VERSION ""

NS_ :

BS_:

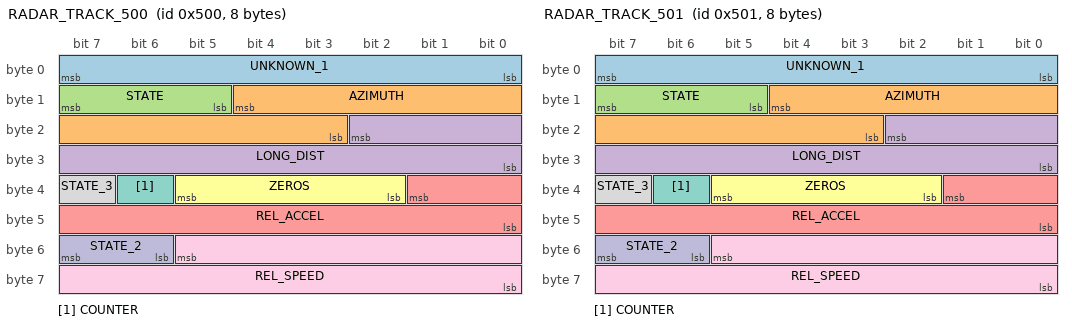
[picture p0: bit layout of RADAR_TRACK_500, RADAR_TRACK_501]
BO_ 1280 RADAR_TRACK_500: 8 RADAR
 SG_ UNKNOWN_1 : 7|8@0- (1,0) [-128|127] "" XXX
 SG_ AZIMUTH : 12|10@0- (0.2,0) [-102.4|102.2] "" XXX
 SG_ STATE : 15|3@0+ (1,0) [0|7] "" XXX
 SG_ LONG_DIST : 18|11@0+ (0.1,0) [0|204.7] "" XXX
 SG_ REL_ACCEL : 33|10@0- (0.02,0) [-10.24|10.22] "" XXX
 SG_ ZEROS : 37|4@0+ (1,0) [0|255] "" XXX
 SG_ COUNTER : 38|1@0+ (1,0) [0|1] "" XXX
 SG_ STATE_3 : 39|1@0+ (1,0) [0|1] "" XXX
 SG_ REL_SPEED : 53|14@0- (0.01,0) [-81.92|81.92] "" XXX
 SG_ STATE_2 : 55|2@0+ (1,0) [0|3] "" XXX

BO_ 1281 RADAR_TRACK_501: 8 RADAR
 SG_ UNKNOWN_1 : 7|8@0- (1,0) [-128|127] "" XXX
 SG_ AZIMUTH : 12|10@0- (0.2,0) [-102.4|102.2] "" XXX
 SG_ STATE : 15|3@0+ (1,0) [0|7] "" XXX
 SG_ LONG_DIST : 18|11@0+ (0.1,0) [0|204.7] "" XXX
 SG_ REL_ACCEL : 33|10@0- (0.02,0) [-10.24|10.22] "" XXX
 SG_ ZEROS : 37|4@0+ (1,0) [0|255] "" XXX
 SG_ COUNTER : 38|1@0+ (1,0) [0|1] "" XXX
 SG_ STATE_3 : 39|1@0+ (1,0) [0|1] "" XXX
 SG_ REL_SPEED : 53|14@0- (0.01,0) [-81.92|81.92] "" XXX
 SG_ STATE_2 : 55|2@0+ (1,0) [0|3] "" XXX

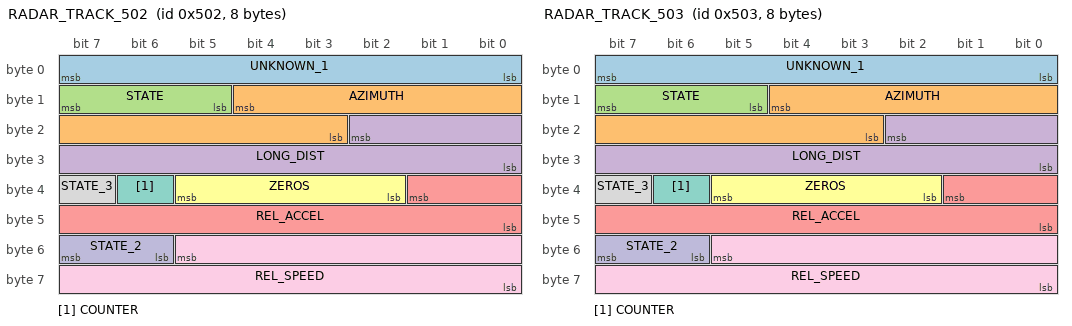
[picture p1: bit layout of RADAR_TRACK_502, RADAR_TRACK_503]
BO_ 1282 RADAR_TRACK_502: 8 RADAR
 SG_ UNKNOWN_1 : 7|8@0- (1,0) [-128|127] "" XXX
 SG_ AZIMUTH : 12|10@0- (0.2,0) [-102.4|102.2] "" XXX
 SG_ STATE : 15|3@0+ (1,0) [0|7] "" XXX
 SG_ LONG_DIST : 18|11@0+ (0.1,0) [0|204.7] "" XXX
 SG_ REL_ACCEL : 33|10@0- (0.02,0) [-10.24|10.22] "" XXX
 SG_ ZEROS : 37|4@0+ (1,0) [0|255] "" XXX
 SG_ COUNTER : 38|1@0+ (1,0) [0|1] "" XXX
 SG_ STATE_3 : 39|1@0+ (1,0) [0|1] "" XXX
 SG_ REL_SPEED : 53|14@0- (0.01,0) [-81.92|81.92] "" XXX
 SG_ STATE_2 : 55|2@0+ (1,0) [0|3] "" XXX

BO_ 1283 RADAR_TRACK_503: 8 RADAR
 SG_ UNKNOWN_1 : 7|8@0- (1,0) [-128|127] "" XXX
 SG_ AZIMUTH : 12|10@0- (0.2,0) [-102.4|102.2] "" XXX
 SG_ STATE : 15|3@0+ (1,0) [0|7] "" XXX
 SG_ LONG_DIST : 18|11@0+ (0.1,0) [0|204.7] "" XXX
 SG_ REL_ACCEL : 33|10@0- (0.02,0) [-10.24|10.22] "" XXX
 SG_ ZEROS : 37|4@0+ (1,0) [0|255] "" XXX
 SG_ COUNTER : 38|1@0+ (1,0) [0|1] "" XXX
 SG_ STATE_3 : 39|1@0+ (1,0) [0|1] "" XXX
 SG_ REL_SPEED : 53|14@0- (0.01,0) [-81.92|81.92] "" XXX
 SG_ STATE_2 : 55|2@0+ (1,0) [0|3] "" XXX

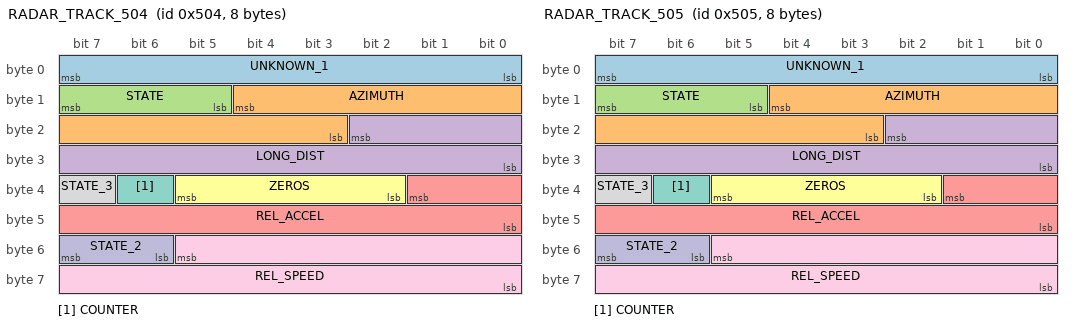
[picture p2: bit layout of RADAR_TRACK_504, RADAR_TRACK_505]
BO_ 1284 RADAR_TRACK_504: 8 RADAR
 SG_ UNKNOWN_1 : 7|8@0- (1,0) [-128|127] "" XXX
 SG_ AZIMUTH : 12|10@0- (0.2,0) [-102.4|102.2] "" XXX
 SG_ STATE : 15|3@0+ (1,0) [0|7] "" XXX
 SG_ LONG_DIST : 18|11@0+ (0.1,0) [0|204.7] "" XXX
 SG_ REL_ACCEL : 33|10@0- (0.02,0) [-10.24|10.22] "" XXX
 SG_ ZEROS : 37|4@0+ (1,0) [0|255] "" XXX
 SG_ COUNTER : 38|1@0+ (1,0) [0|1] "" XXX
 SG_ STATE_3 : 39|1@0+ (1,0) [0|1] "" XXX
 SG_ REL_SPEED : 53|14@0- (0.01,0) [-81.92|81.92] "" XXX
 SG_ STATE_2 : 55|2@0+ (1,0) [0|3] "" XXX

BO_ 1285 RADAR_TRACK_505: 8 RADAR
 SG_ UNKNOWN_1 : 7|8@0- (1,0) [-128|127] "" XXX
 SG_ AZIMUTH : 12|10@0- (0.2,0) [-102.4|102.2] "" XXX
 SG_ STATE : 15|3@0+ (1,0) [0|7] "" XXX
 SG_ LONG_DIST : 18|11@0+ (0.1,0) [0|204.7] "" XXX
 SG_ REL_ACCEL : 33|10@0- (0.02,0) [-10.24|10.22] "" XXX
 SG_ ZEROS : 37|4@0+ (1,0) [0|255] "" XXX
 SG_ COUNTER : 38|1@0+ (1,0) [0|1] "" XXX
 SG_ STATE_3 : 39|1@0+ (1,0) [0|1] "" XXX
 SG_ REL_SPEED : 53|14@0- (0.01,0) [-81.92|81.92] "" XXX
 SG_ STATE_2 : 55|2@0+ (1,0) [0|3] "" XXX

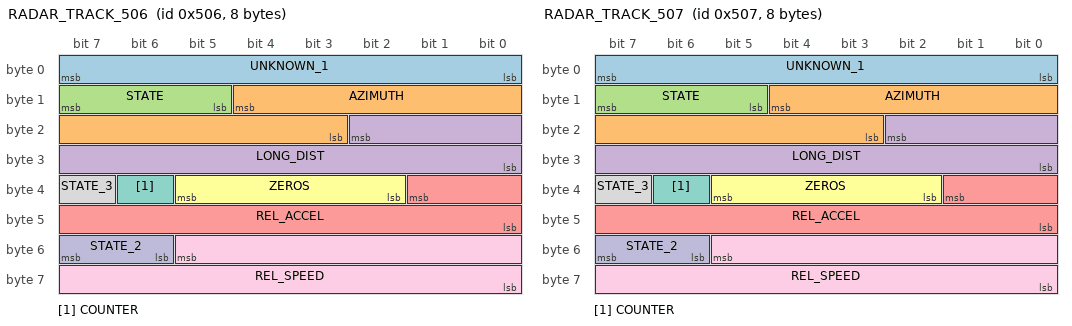
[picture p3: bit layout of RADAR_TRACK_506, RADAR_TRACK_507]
BO_ 1286 RADAR_TRACK_506: 8 RADAR
 SG_ UNKNOWN_1 : 7|8@0- (1,0) [-128|127] "" XXX
 SG_ AZIMUTH : 12|10@0- (0.2,0) [-102.4|102.2] "" XXX
 SG_ STATE : 15|3@0+ (1,0) [0|7] "" XXX
 SG_ LONG_DIST : 18|11@0+ (0.1,0) [0|204.7] "" XXX
 SG_ REL_ACCEL : 33|10@0- (0.02,0) [-10.24|10.22] "" XXX
 SG_ ZEROS : 37|4@0+ (1,0) [0|255] "" XXX
 SG_ COUNTER : 38|1@0+ (1,0) [0|1] "" XXX
 SG_ STATE_3 : 39|1@0+ (1,0) [0|1] "" XXX
 SG_ REL_SPEED : 53|14@0- (0.01,0) [-81.92|81.92] "" XXX
 SG_ STATE_2 : 55|2@0+ (1,0) [0|3] "" XXX

BO_ 1287 RADAR_TRACK_507: 8 RADAR
 SG_ UNKNOWN_1 : 7|8@0- (1,0) [-128|127] "" XXX
 SG_ AZIMUTH : 12|10@0- (0.2,0) [-102.4|102.2] "" XXX
 SG_ STATE : 15|3@0+ (1,0) [0|7] "" XXX
 SG_ LONG_DIST : 18|11@0+ (0.1,0) [0|204.7] "" XXX
 SG_ REL_ACCEL : 33|10@0- (0.02,0) [-10.24|10.22] "" XXX
 SG_ ZEROS : 37|4@0+ (1,0) [0|255] "" XXX
 SG_ COUNTER : 38|1@0+ (1,0) [0|1] "" XXX
 SG_ STATE_3 : 39|1@0+ (1,0) [0|1] "" XXX
 SG_ REL_SPEED : 53|14@0- (0.01,0) [-81.92|81.92] "" XXX
 SG_ STATE_2 : 55|2@0+ (1,0) [0|3] "" XXX

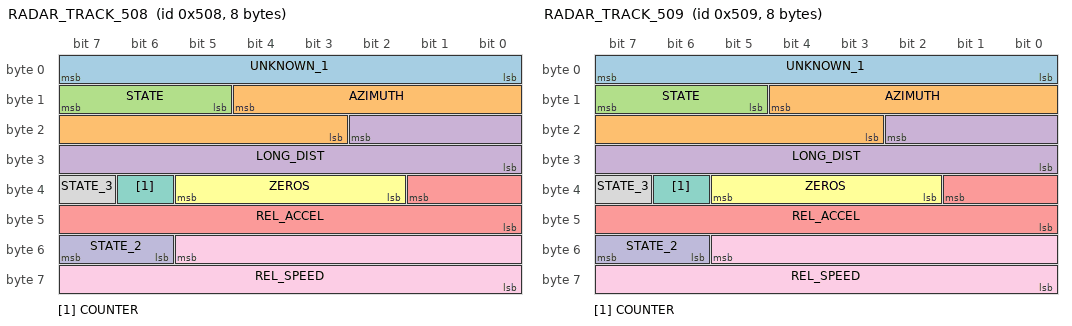
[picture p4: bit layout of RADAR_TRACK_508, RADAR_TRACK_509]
BO_ 1288 RADAR_TRACK_508: 8 RADAR
 SG_ UNKNOWN_1 : 7|8@0- (1,0) [-128|127] "" XXX
 SG_ AZIMUTH : 12|10@0- (0.2,0) [-102.4|102.2] "" XXX
 SG_ STATE : 15|3@0+ (1,0) [0|7] "" XXX
 SG_ LONG_DIST : 18|11@0+ (0.1,0) [0|204.7] "" XXX
 SG_ REL_ACCEL : 33|10@0- (0.02,0) [-10.24|10.22] "" XXX
 SG_ ZEROS : 37|4@0+ (1,0) [0|255] "" XXX
 SG_ COUNTER : 38|1@0+ (1,0) [0|1] "" XXX
 SG_ STATE_3 : 39|1@0+ (1,0) [0|1] "" XXX
 SG_ REL_SPEED : 53|14@0- (0.01,0) [-81.92|81.92] "" XXX
 SG_ STATE_2 : 55|2@0+ (1,0) [0|3] "" XXX

BO_ 1289 RADAR_TRACK_509: 8 RADAR
 SG_ UNKNOWN_1 : 7|8@0- (1,0) [-128|127] "" XXX
 SG_ AZIMUTH : 12|10@0- (0.2,0) [-102.4|102.2] "" XXX
 SG_ STATE : 15|3@0+ (1,0) [0|7] "" XXX
 SG_ LONG_DIST : 18|11@0+ (0.1,0) [0|204.7] "" XXX
 SG_ REL_ACCEL : 33|10@0- (0.02,0) [-10.24|10.22] "" XXX
 SG_ ZEROS : 37|4@0+ (1,0) [0|255] "" XXX
 SG_ COUNTER : 38|1@0+ (1,0) [0|1] "" XXX
 SG_ STATE_3 : 39|1@0+ (1,0) [0|1] "" XXX
 SG_ REL_SPEED : 53|14@0- (0.01,0) [-81.92|81.92] "" XXX
 SG_ STATE_2 : 55|2@0+ (1,0) [0|3] "" XXX

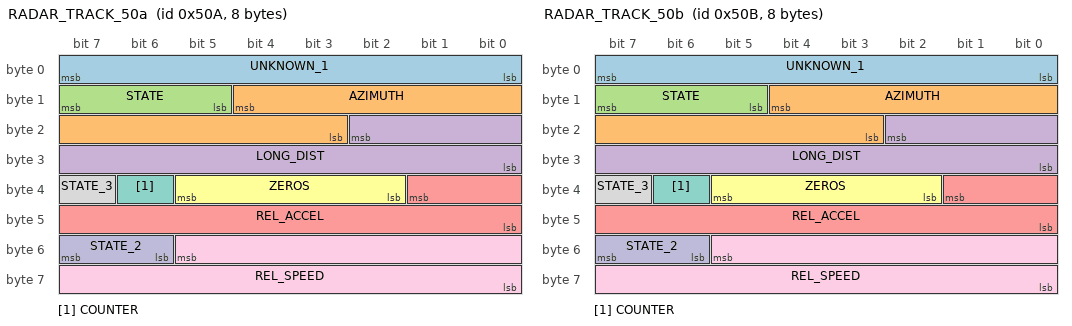
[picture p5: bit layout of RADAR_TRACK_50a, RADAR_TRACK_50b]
BO_ 1290 RADAR_TRACK_50a: 8 RADAR
 SG_ UNKNOWN_1 : 7|8@0- (1,0) [-128|127] "" XXX
 SG_ AZIMUTH : 12|10@0- (0.2,0) [-102.4|102.2] "" XXX
 SG_ STATE : 15|3@0+ (1,0) [0|7] "" XXX
 SG_ LONG_DIST : 18|11@0+ (0.1,0) [0|204.7] "" XXX
 SG_ REL_ACCEL : 33|10@0- (0.02,0) [-10.24|10.22] "" XXX
 SG_ ZEROS : 37|4@0+ (1,0) [0|255] "" XXX
 SG_ COUNTER : 38|1@0+ (1,0) [0|1] "" XXX
 SG_ STATE_3 : 39|1@0+ (1,0) [0|1] "" XXX
 SG_ REL_SPEED : 53|14@0- (0.01,0) [-81.92|81.92] "" XXX
 SG_ STATE_2 : 55|2@0+ (1,0) [0|3] "" XXX

BO_ 1291 RADAR_TRACK_50b: 8 RADAR
 SG_ UNKNOWN_1 : 7|8@0- (1,0) [-128|127] "" XXX
 SG_ AZIMUTH : 12|10@0- (0.2,0) [-102.4|102.2] "" XXX
 SG_ STATE : 15|3@0+ (1,0) [0|7] "" XXX
 SG_ LONG_DIST : 18|11@0+ (0.1,0) [0|204.7] "" XXX
 SG_ REL_ACCEL : 33|10@0- (0.02,0) [-10.24|10.22] "" XXX
 SG_ ZEROS : 37|4@0+ (1,0) [0|255] "" XXX
 SG_ COUNTER : 38|1@0+ (1,0) [0|1] "" XXX
 SG_ STATE_3 : 39|1@0+ (1,0) [0|1] "" XXX
 SG_ REL_SPEED : 53|14@0- (0.01,0) [-81.92|81.92] "" XXX
 SG_ STATE_2 : 55|2@0+ (1,0) [0|3] "" XXX

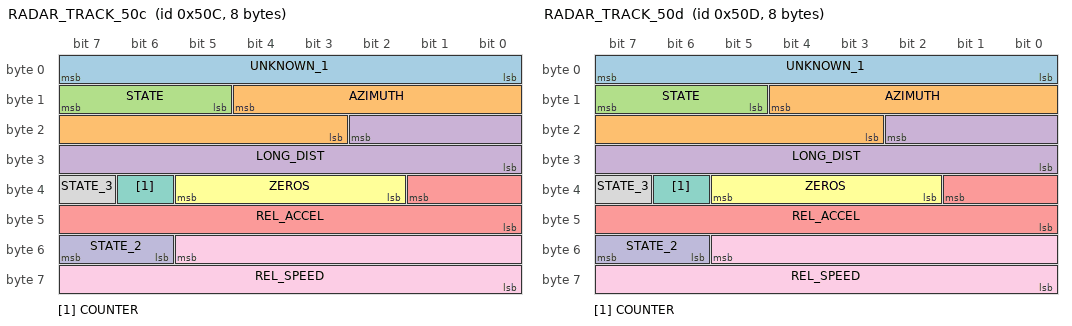
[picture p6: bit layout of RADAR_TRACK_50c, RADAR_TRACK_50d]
BO_ 1292 RADAR_TRACK_50c: 8 RADAR
 SG_ UNKNOWN_1 : 7|8@0- (1,0) [-128|127] "" XXX
 SG_ AZIMUTH : 12|10@0- (0.2,0) [-102.4|102.2] "" XXX
 SG_ STATE : 15|3@0+ (1,0) [0|7] "" XXX
 SG_ LONG_DIST : 18|11@0+ (0.1,0) [0|204.7] "" XXX
 SG_ REL_ACCEL : 33|10@0- (0.02,0) [-10.24|10.22] "" XXX
 SG_ ZEROS : 37|4@0+ (1,0) [0|255] "" XXX
 SG_ COUNTER : 38|1@0+ (1,0) [0|1] "" XXX
 SG_ STATE_3 : 39|1@0+ (1,0) [0|1] "" XXX
 SG_ REL_SPEED : 53|14@0- (0.01,0) [-81.92|81.92] "" XXX
 SG_ STATE_2 : 55|2@0+ (1,0) [0|3] "" XXX

BO_ 1293 RADAR_TRACK_50d: 8 RADAR
 SG_ UNKNOWN_1 : 7|8@0- (1,0) [-128|127] "" XXX
 SG_ AZIMUTH : 12|10@0- (0.2,0) [-102.4|102.2] "" XXX
 SG_ STATE : 15|3@0+ (1,0) [0|7] "" XXX
 SG_ LONG_DIST : 18|11@0+ (0.1,0) [0|204.7] "" XXX
 SG_ REL_ACCEL : 33|10@0- (0.02,0) [-10.24|10.22] "" XXX
 SG_ ZEROS : 37|4@0+ (1,0) [0|255] "" XXX
 SG_ COUNTER : 38|1@0+ (1,0) [0|1] "" XXX
 SG_ STATE_3 : 39|1@0+ (1,0) [0|1] "" XXX
 SG_ REL_SPEED : 53|14@0- (0.01,0) [-81.92|81.92] "" XXX
 SG_ STATE_2 : 55|2@0+ (1,0) [0|3] "" XXX

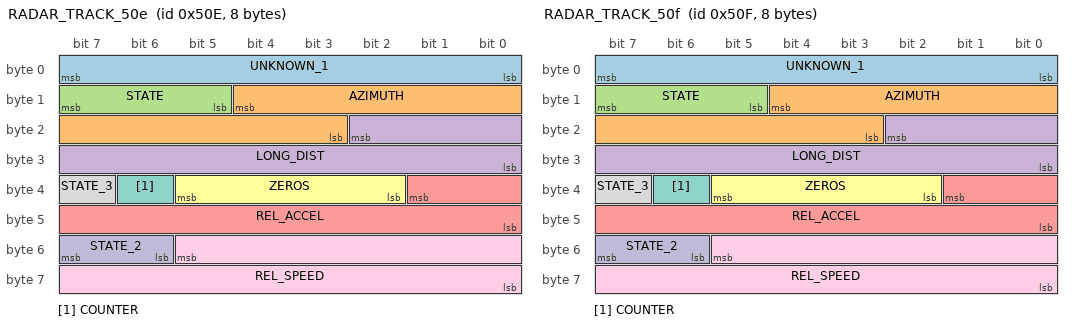
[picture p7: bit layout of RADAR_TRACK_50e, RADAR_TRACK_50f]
BO_ 1294 RADAR_TRACK_50e: 8 RADAR
 SG_ UNKNOWN_1 : 7|8@0- (1,0) [-128|127] "" XXX
 SG_ AZIMUTH : 12|10@0- (0.2,0) [-102.4|102.2] "" XXX
 SG_ STATE : 15|3@0+ (1,0) [0|7] "" XXX
 SG_ LONG_DIST : 18|11@0+ (0.1,0) [0|204.7] "" XXX
 SG_ REL_ACCEL : 33|10@0- (0.02,0) [-10.24|10.22] "" XXX
 SG_ ZEROS : 37|4@0+ (1,0) [0|255] "" XXX
 SG_ COUNTER : 38|1@0+ (1,0) [0|1] "" XXX
 SG_ STATE_3 : 39|1@0+ (1,0) [0|1] "" XXX
 SG_ REL_SPEED : 53|14@0- (0.01,0) [-81.92|81.92] "" XXX
 SG_ STATE_2 : 55|2@0+ (1,0) [0|3] "" XXX

BO_ 1295 RADAR_TRACK_50f: 8 RADAR
 SG_ UNKNOWN_1 : 7|8@0- (1,0) [-128|127] "" XXX
 SG_ AZIMUTH : 12|10@0- (0.2,0) [-102.4|102.2] "" XXX
 SG_ STATE : 15|3@0+ (1,0) [0|7] "" XXX
 SG_ LONG_DIST : 18|11@0+ (0.1,0) [0|204.7] "" XXX
 SG_ REL_ACCEL : 33|10@0- (0.02,0) [-10.24|10.22] "" XXX
 SG_ ZEROS : 37|4@0+ (1,0) [0|255] "" XXX
 SG_ COUNTER : 38|1@0+ (1,0) [0|1] "" XXX
 SG_ STATE_3 : 39|1@0+ (1,0) [0|1] "" XXX
 SG_ REL_SPEED : 53|14@0- (0.01,0) [-81.92|81.92] "" XXX
 SG_ STATE_2 : 55|2@0+ (1,0) [0|3] "" XXX

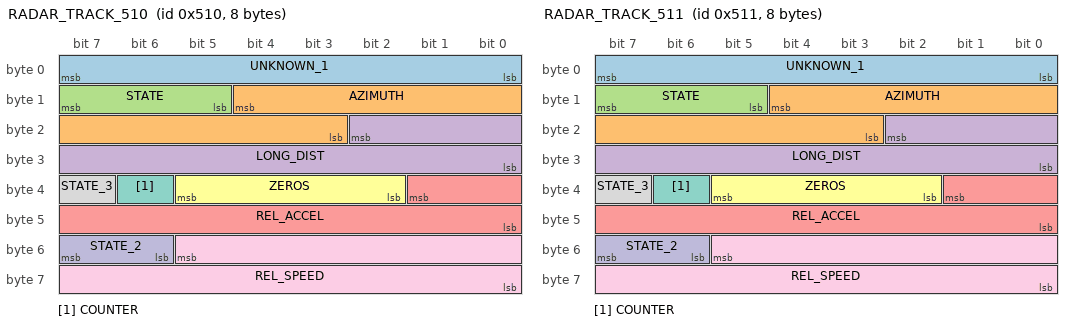
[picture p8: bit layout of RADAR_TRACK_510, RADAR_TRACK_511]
BO_ 1296 RADAR_TRACK_510: 8 RADAR
 SG_ UNKNOWN_1 : 7|8@0- (1,0) [-128|127] "" XXX
 SG_ AZIMUTH : 12|10@0- (0.2,0) [-102.4|102.2] "" XXX
 SG_ STATE : 15|3@0+ (1,0) [0|7] "" XXX
 SG_ LONG_DIST : 18|11@0+ (0.1,0) [0|204.7] "" XXX
 SG_ REL_ACCEL : 33|10@0- (0.02,0) [-10.24|10.22] "" XXX
 SG_ ZEROS : 37|4@0+ (1,0) [0|255] "" XXX
 SG_ COUNTER : 38|1@0+ (1,0) [0|1] "" XXX
 SG_ STATE_3 : 39|1@0+ (1,0) [0|1] "" XXX
 SG_ REL_SPEED : 53|14@0- (0.01,0) [-81.92|81.92] "" XXX
 SG_ STATE_2 : 55|2@0+ (1,0) [0|3] "" XXX

BO_ 1297 RADAR_TRACK_511: 8 RADAR
 SG_ UNKNOWN_1 : 7|8@0- (1,0) [-128|127] "" XXX
 SG_ AZIMUTH : 12|10@0- (0.2,0) [-102.4|102.2] "" XXX
 SG_ STATE : 15|3@0+ (1,0) [0|7] "" XXX
 SG_ LONG_DIST : 18|11@0+ (0.1,0) [0|204.7] "" XXX
 SG_ REL_ACCEL : 33|10@0- (0.02,0) [-10.24|10.22] "" XXX
 SG_ ZEROS : 37|4@0+ (1,0) [0|255] "" XXX
 SG_ COUNTER : 38|1@0+ (1,0) [0|1] "" XXX
 SG_ STATE_3 : 39|1@0+ (1,0) [0|1] "" XXX
 SG_ REL_SPEED : 53|14@0- (0.01,0) [-81.92|81.92] "" XXX
 SG_ STATE_2 : 55|2@0+ (1,0) [0|3] "" XXX

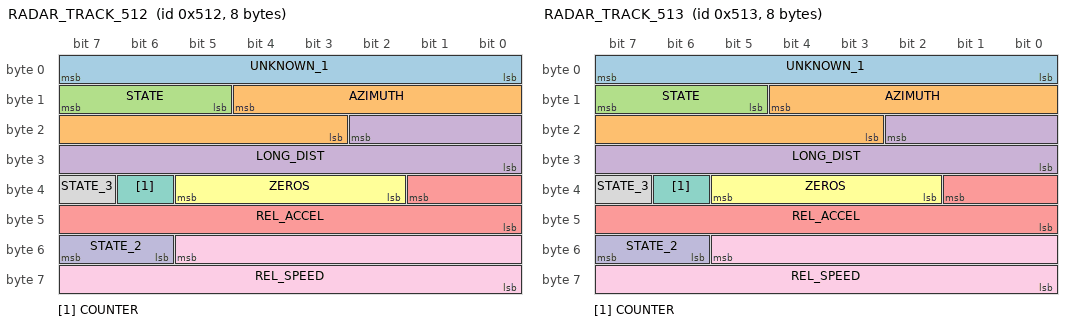
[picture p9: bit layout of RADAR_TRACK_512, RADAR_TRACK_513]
BO_ 1298 RADAR_TRACK_512: 8 RADAR
 SG_ UNKNOWN_1 : 7|8@0- (1,0) [-128|127] "" XXX
 SG_ AZIMUTH : 12|10@0- (0.2,0) [-102.4|102.2] "" XXX
 SG_ STATE : 15|3@0+ (1,0) [0|7] "" XXX
 SG_ LONG_DIST : 18|11@0+ (0.1,0) [0|204.7] "" XXX
 SG_ REL_ACCEL : 33|10@0- (0.02,0) [-10.24|10.22] "" XXX
 SG_ ZEROS : 37|4@0+ (1,0) [0|255] "" XXX
 SG_ COUNTER : 38|1@0+ (1,0) [0|1] "" XXX
 SG_ STATE_3 : 39|1@0+ (1,0) [0|1] "" XXX
 SG_ REL_SPEED : 53|14@0- (0.01,0) [-81.92|81.92] "" XXX
 SG_ STATE_2 : 55|2@0+ (1,0) [0|3] "" XXX

BO_ 1299 RADAR_TRACK_513: 8 RADAR
 SG_ UNKNOWN_1 : 7|8@0- (1,0) [-128|127] "" XXX
 SG_ AZIMUTH : 12|10@0- (0.2,0) [-102.4|102.2] "" XXX
 SG_ STATE : 15|3@0+ (1,0) [0|7] "" XXX
 SG_ LONG_DIST : 18|11@0+ (0.1,0) [0|204.7] "" XXX
 SG_ REL_ACCEL : 33|10@0- (0.02,0) [-10.24|10.22] "" XXX
 SG_ ZEROS : 37|4@0+ (1,0) [0|255] "" XXX
 SG_ COUNTER : 38|1@0+ (1,0) [0|1] "" XXX
 SG_ STATE_3 : 39|1@0+ (1,0) [0|1] "" XXX
 SG_ REL_SPEED : 53|14@0- (0.01,0) [-81.92|81.92] "" XXX
 SG_ STATE_2 : 55|2@0+ (1,0) [0|3] "" XXX

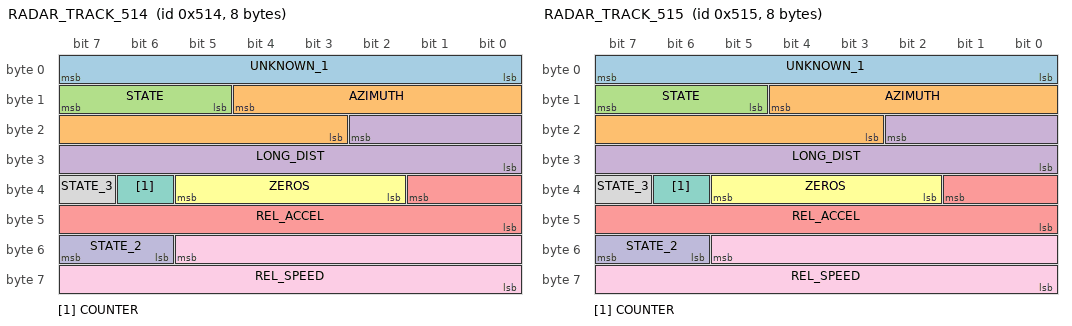
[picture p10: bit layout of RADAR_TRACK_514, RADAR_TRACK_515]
BO_ 1300 RADAR_TRACK_514: 8 RADAR
 SG_ UNKNOWN_1 : 7|8@0- (1,0) [-128|127] "" XXX
 SG_ AZIMUTH : 12|10@0- (0.2,0) [-102.4|102.2] "" XXX
 SG_ STATE : 15|3@0+ (1,0) [0|7] "" XXX
 SG_ LONG_DIST : 18|11@0+ (0.1,0) [0|204.7] "" XXX
 SG_ REL_ACCEL : 33|10@0- (0.02,0) [-10.24|10.22] "" XXX
 SG_ ZEROS : 37|4@0+ (1,0) [0|255] "" XXX
 SG_ COUNTER : 38|1@0+ (1,0) [0|1] "" XXX
 SG_ STATE_3 : 39|1@0+ (1,0) [0|1] "" XXX
 SG_ REL_SPEED : 53|14@0- (0.01,0) [-81.92|81.92] "" XXX
 SG_ STATE_2 : 55|2@0+ (1,0) [0|3] "" XXX

BO_ 1301 RADAR_TRACK_515: 8 RADAR
 SG_ UNKNOWN_1 : 7|8@0- (1,0) [-128|127] "" XXX
 SG_ AZIMUTH : 12|10@0- (0.2,0) [-102.4|102.2] "" XXX
 SG_ STATE : 15|3@0+ (1,0) [0|7] "" XXX
 SG_ LONG_DIST : 18|11@0+ (0.1,0) [0|204.7] "" XXX
 SG_ REL_ACCEL : 33|10@0- (0.02,0) [-10.24|10.22] "" XXX
 SG_ ZEROS : 37|4@0+ (1,0) [0|255] "" XXX
 SG_ COUNTER : 38|1@0+ (1,0) [0|1] "" XXX
 SG_ STATE_3 : 39|1@0+ (1,0) [0|1] "" XXX
 SG_ REL_SPEED : 53|14@0- (0.01,0) [-81.92|81.92] "" XXX
 SG_ STATE_2 : 55|2@0+ (1,0) [0|3] "" XXX

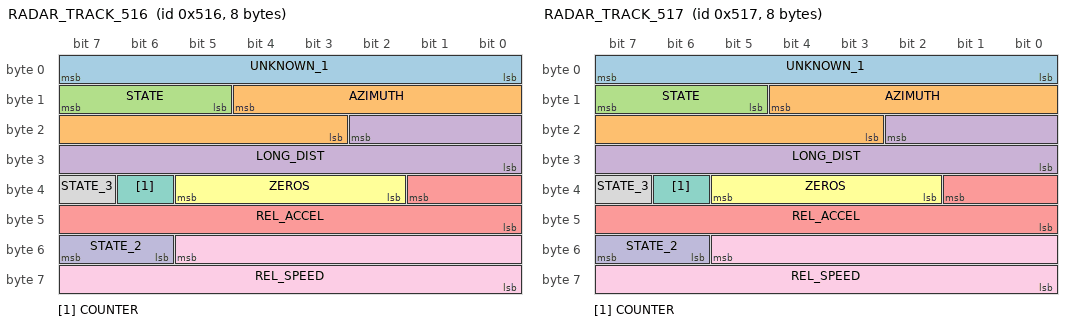
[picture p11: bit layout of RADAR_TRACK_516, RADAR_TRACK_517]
BO_ 1302 RADAR_TRACK_516: 8 RADAR
 SG_ UNKNOWN_1 : 7|8@0- (1,0) [-128|127] "" XXX
 SG_ AZIMUTH : 12|10@0- (0.2,0) [-102.4|102.2] "" XXX
 SG_ STATE : 15|3@0+ (1,0) [0|7] "" XXX
 SG_ LONG_DIST : 18|11@0+ (0.1,0) [0|204.7] "" XXX
 SG_ REL_ACCEL : 33|10@0- (0.02,0) [-10.24|10.22] "" XXX
 SG_ ZEROS : 37|4@0+ (1,0) [0|255] "" XXX
 SG_ COUNTER : 38|1@0+ (1,0) [0|1] "" XXX
 SG_ STATE_3 : 39|1@0+ (1,0) [0|1] "" XXX
 SG_ REL_SPEED : 53|14@0- (0.01,0) [-81.92|81.92] "" XXX
 SG_ STATE_2 : 55|2@0+ (1,0) [0|3] "" XXX

BO_ 1303 RADAR_TRACK_517: 8 RADAR
 SG_ UNKNOWN_1 : 7|8@0- (1,0) [-128|127] "" XXX
 SG_ AZIMUTH : 12|10@0- (0.2,0) [-102.4|102.2] "" XXX
 SG_ STATE : 15|3@0+ (1,0) [0|7] "" XXX
 SG_ LONG_DIST : 18|11@0+ (0.1,0) [0|204.7] "" XXX
 SG_ REL_ACCEL : 33|10@0- (0.02,0) [-10.24|10.22] "" XXX
 SG_ ZEROS : 37|4@0+ (1,0) [0|255] "" XXX
 SG_ COUNTER : 38|1@0+ (1,0) [0|1] "" XXX
 SG_ STATE_3 : 39|1@0+ (1,0) [0|1] "" XXX
 SG_ REL_SPEED : 53|14@0- (0.01,0) [-81.92|81.92] "" XXX
 SG_ STATE_2 : 55|2@0+ (1,0) [0|3] "" XXX

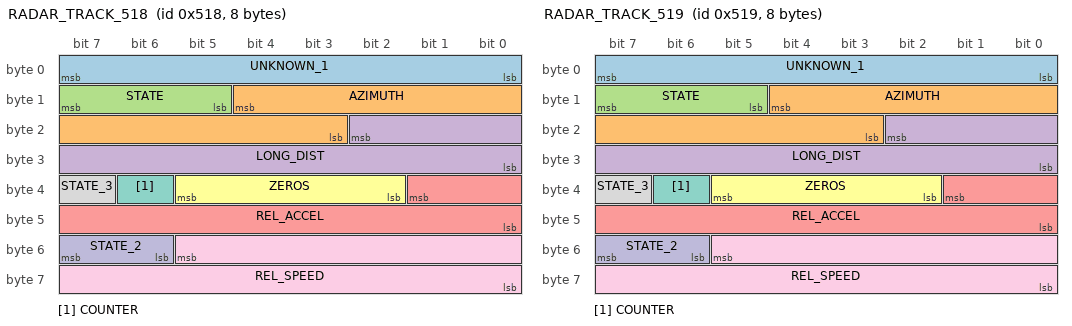
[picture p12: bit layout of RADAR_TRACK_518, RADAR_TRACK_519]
BO_ 1304 RADAR_TRACK_518: 8 RADAR
 SG_ UNKNOWN_1 : 7|8@0- (1,0) [-128|127] "" XXX
 SG_ AZIMUTH : 12|10@0- (0.2,0) [-102.4|102.2] "" XXX
 SG_ STATE : 15|3@0+ (1,0) [0|7] "" XXX
 SG_ LONG_DIST : 18|11@0+ (0.1,0) [0|204.7] "" XXX
 SG_ REL_ACCEL : 33|10@0- (0.02,0) [-10.24|10.22] "" XXX
 SG_ ZEROS : 37|4@0+ (1,0) [0|255] "" XXX
 SG_ COUNTER : 38|1@0+ (1,0) [0|1] "" XXX
 SG_ STATE_3 : 39|1@0+ (1,0) [0|1] "" XXX
 SG_ REL_SPEED : 53|14@0- (0.01,0) [-81.92|81.92] "" XXX
 SG_ STATE_2 : 55|2@0+ (1,0) [0|3] "" XXX

BO_ 1305 RADAR_TRACK_519: 8 RADAR
 SG_ UNKNOWN_1 : 7|8@0- (1,0) [-128|127] "" XXX
 SG_ AZIMUTH : 12|10@0- (0.2,0) [-102.4|102.2] "" XXX
 SG_ STATE : 15|3@0+ (1,0) [0|7] "" XXX
 SG_ LONG_DIST : 18|11@0+ (0.1,0) [0|204.7] "" XXX
 SG_ REL_ACCEL : 33|10@0- (0.02,0) [-10.24|10.22] "" XXX
 SG_ ZEROS : 37|4@0+ (1,0) [0|255] "" XXX
 SG_ COUNTER : 38|1@0+ (1,0) [0|1] "" XXX
 SG_ STATE_3 : 39|1@0+ (1,0) [0|1] "" XXX
 SG_ REL_SPEED : 53|14@0- (0.01,0) [-81.92|81.92] "" XXX
 SG_ STATE_2 : 55|2@0+ (1,0) [0|3] "" XXX

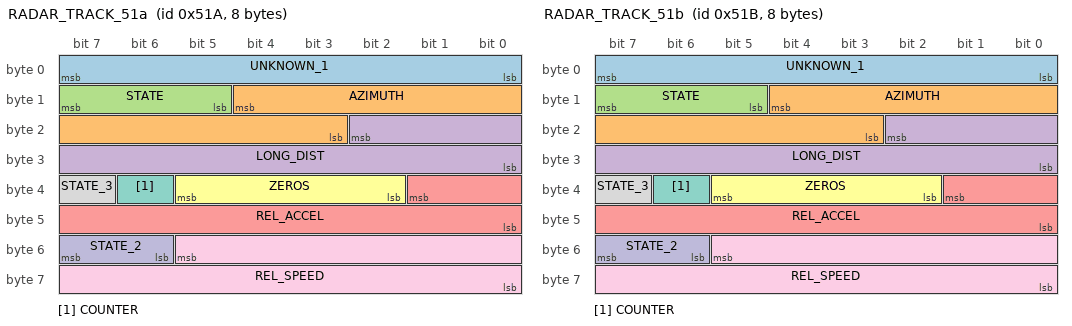
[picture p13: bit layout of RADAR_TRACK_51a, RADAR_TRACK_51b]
BO_ 1306 RADAR_TRACK_51a: 8 RADAR
 SG_ UNKNOWN_1 : 7|8@0- (1,0) [-128|127] "" XXX
 SG_ AZIMUTH : 12|10@0- (0.2,0) [-102.4|102.2] "" XXX
 SG_ STATE : 15|3@0+ (1,0) [0|7] "" XXX
 SG_ LONG_DIST : 18|11@0+ (0.1,0) [0|204.7] "" XXX
 SG_ REL_ACCEL : 33|10@0- (0.02,0) [-10.24|10.22] "" XXX
 SG_ ZEROS : 37|4@0+ (1,0) [0|255] "" XXX
 SG_ COUNTER : 38|1@0+ (1,0) [0|1] "" XXX
 SG_ STATE_3 : 39|1@0+ (1,0) [0|1] "" XXX
 SG_ REL_SPEED : 53|14@0- (0.01,0) [-81.92|81.92] "" XXX
 SG_ STATE_2 : 55|2@0+ (1,0) [0|3] "" XXX

BO_ 1307 RADAR_TRACK_51b: 8 RADAR
 SG_ UNKNOWN_1 : 7|8@0- (1,0) [-128|127] "" XXX
 SG_ AZIMUTH : 12|10@0- (0.2,0) [-102.4|102.2] "" XXX
 SG_ STATE : 15|3@0+ (1,0) [0|7] "" XXX
 SG_ LONG_DIST : 18|11@0+ (0.1,0) [0|204.7] "" XXX
 SG_ REL_ACCEL : 33|10@0- (0.02,0) [-10.24|10.22] "" XXX
 SG_ ZEROS : 37|4@0+ (1,0) [0|255] "" XXX
 SG_ COUNTER : 38|1@0+ (1,0) [0|1] "" XXX
 SG_ STATE_3 : 39|1@0+ (1,0) [0|1] "" XXX
 SG_ REL_SPEED : 53|14@0- (0.01,0) [-81.92|81.92] "" XXX
 SG_ STATE_2 : 55|2@0+ (1,0) [0|3] "" XXX

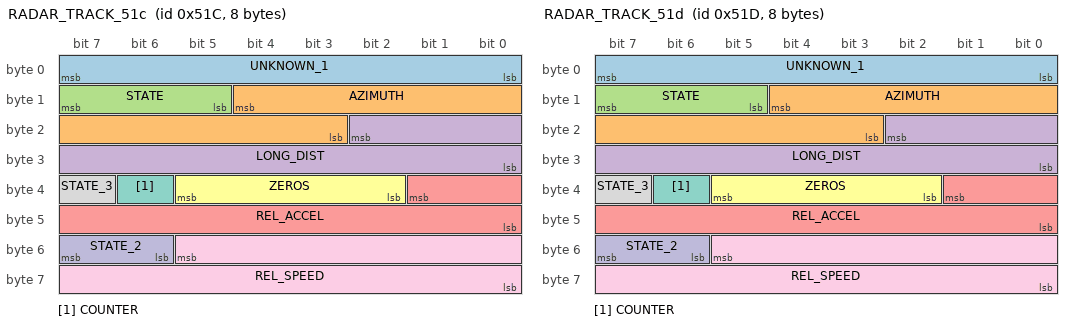
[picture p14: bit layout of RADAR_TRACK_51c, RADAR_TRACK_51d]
BO_ 1308 RADAR_TRACK_51c: 8 RADAR
 SG_ UNKNOWN_1 : 7|8@0- (1,0) [-128|127] "" XXX
 SG_ AZIMUTH : 12|10@0- (0.2,0) [-102.4|102.2] "" XXX
 SG_ STATE : 15|3@0+ (1,0) [0|7] "" XXX
 SG_ LONG_DIST : 18|11@0+ (0.1,0) [0|204.7] "" XXX
 SG_ REL_ACCEL : 33|10@0- (0.02,0) [-10.24|10.22] "" XXX
 SG_ ZEROS : 37|4@0+ (1,0) [0|255] "" XXX
 SG_ COUNTER : 38|1@0+ (1,0) [0|1] "" XXX
 SG_ STATE_3 : 39|1@0+ (1,0) [0|1] "" XXX
 SG_ REL_SPEED : 53|14@0- (0.01,0) [-81.92|81.92] "" XXX
 SG_ STATE_2 : 55|2@0+ (1,0) [0|3] "" XXX

BO_ 1309 RADAR_TRACK_51d: 8 RADAR
 SG_ UNKNOWN_1 : 7|8@0- (1,0) [-128|127] "" XXX
 SG_ AZIMUTH : 12|10@0- (0.2,0) [-102.4|102.2] "" XXX
 SG_ STATE : 15|3@0+ (1,0) [0|7] "" XXX
 SG_ LONG_DIST : 18|11@0+ (0.1,0) [0|204.7] "" XXX
 SG_ REL_ACCEL : 33|10@0- (0.02,0) [-10.24|10.22] "" XXX
 SG_ ZEROS : 37|4@0+ (1,0) [0|255] "" XXX
 SG_ COUNTER : 38|1@0+ (1,0) [0|1] "" XXX
 SG_ STATE_3 : 39|1@0+ (1,0) [0|1] "" XXX
 SG_ REL_SPEED : 53|14@0- (0.01,0) [-81.92|81.92] "" XXX
 SG_ STATE_2 : 55|2@0+ (1,0) [0|3] "" XXX

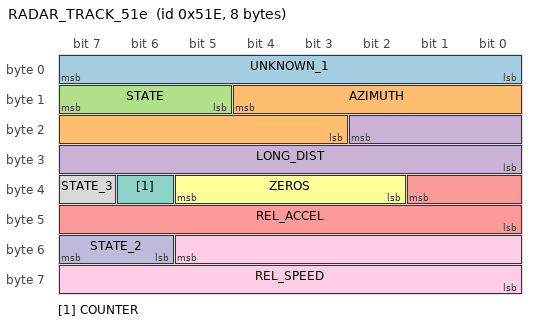
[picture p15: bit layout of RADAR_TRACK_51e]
BO_ 1310 RADAR_TRACK_51e: 8 RADAR
 SG_ UNKNOWN_1 : 7|8@0- (1,0) [-128|127] "" XXX
 SG_ AZIMUTH : 12|10@0- (0.2,0) [-102.4|102.2] "" XXX
 SG_ STATE : 15|3@0+ (1,0) [0|7] "" XXX
 SG_ LONG_DIST : 18|11@0+ (0.1,0) [0|204.7] "" XXX
 SG_ REL_ACCEL : 33|10@0- (0.02,0) [-10.24|10.22] "" XXX
 SG_ ZEROS : 37|4@0+ (1,0) [0|255] "" XXX
 SG_ COUNTER : 38|1@0+ (1,0) [0|1] "" XXX
 SG_ STATE_3 : 39|1@0+ (1,0) [0|1] "" XXX
 SG_ REL_SPEED : 53|14@0- (0.01,0) [-81.92|81.92] "" XXX
 SG_ STATE_2 : 55|2@0+ (1,0) [0|3] "" XXX

BU_: IAP ODS _4WD BCM HUD DATC MDPS AAF_Tester AEMC SMK _4WD EPB CUBIS MTS TMU EVP CGW TPMS LPI DI_BOX SPAS EMS LCA TCU IBOX FATC AFLS FPCM SCC AHLS AVM ABS SNV OPI PGS SAS AAF Dummy LDWS_LKAS LVR ESC PSB CLU ECS ACU REA

CM_ "AUTOGENERATED FILE, DO NOT EDIT";

CM_ "Imported file _honda_common.dbc starts here";
CM_ SG_ 304 "Seems to be platform-agnostic";
CM_ SG_ 316 "Should exist on Nidec";
CM_ SG_ 420 BRAKE_HOLD_RELATED "On when Brake Hold engaged";
CM_ SG_ 490 LONG_ACCEL "wheel speed derivative, noisy and zero snapping";
CM_ SG_ 773 PASS_AIRBAG_ON "Might just be indicator light";
CM_ SG_ 773 PASS_AIRBAG_OFF "Might just be indicator light";
CM_ SG_ 780 CRUISE_SPEED "255 = no speed";
CM_ SG_ 780 PCM_SPEED "Used by Nidec";
CM_ SG_ 780 PCM_GAS "Used by Nidec";
CM_ SG_ 804 CRUISE_SPEED_PCM "255 = no speed";

CM_ "Imported file _bosch_2018.dbc starts here";
CM_ SG_ 450 EPB_STATE "3: On, 2: Disengaging, 1: Engaging, 0: Off";
CM_ SG_ 576 LINE_DISTANCE_VISIBLE "Length of line visible, undecoded";
CM_ SG_ 577 LINE_FAR_EDGE_POSITION "Appears to be a measure of line thickness, indicates location of the portion of the line furthest from the car, undecoded";
CM_ SG_ 577 LINE_PARAMETER "Unclear if this is low quality line curvature rate or if this is something else, but it is correlated with line curvature, undecoded";
CM_ SG_ 577 LINE_DASHED "1 = line is dashed";
CM_ SG_ 577 LINE_SOLID "1 = line is solid";

CM_ "Imported file _bosch_adas_2018.dbc starts here";
CM_ SG_ 479 CONTROL_ON "Set to 5 when car is being controlled";
CM_ SG_ 479 AEB_STATUS "set for the duration of AEB event";
CM_ SG_ 479 AEB_BRAKING "set when braking is commanded during AEB event";
CM_ SG_ 479 AEB_PREPARE "set 1s before AEB";
CM_ SG_ 829 BEEP "beeps are pleasant, chimes are for warnngs etc...";

CM_ "Imported file _steering_sensors_a.dbc starts here";
CM_ "honda_civic_hatchback_ex_2017_can.dbc starts here";

VAL_ 780 CRUISE_SPEED 255 "no_speed" 252 "stopped";
VAL_ 780 HUD_LEAD 3 "acc_off" 2 "solid_car" 1 "dashed_car" 0 "no_car";
VAL_ 884 DASHBOARD_ALERT 0 "none" 51 "acc_problem" 55 "cmbs_problem" 75 "key_not_detected" 79 "fasten_seatbelt" 111 "lkas_problem" 131 "brake_system_problem" 132 "brake_hold_problem" 139 "tbd" 161 "door_open";
VAL_ 891 WIPERS 4 "High" 2 "Low" 0 "Off";

VAL_ 399 STEER_STATUS 6 "tmp_fault" 5 "fault_1" 4 "no_torque_alert_2" 3 "low_speed_lockout" 2 "no_torque_alert_1" 0 "normal";

VAL_ 829 BEEP 3 "single_beep" 2 "triple_beep" 1 "repeated_beep" 0 "no_beep";

VAL_ 401 GEAR_SHIFTER 32 "L" 16 "S" 8 "D" 4 "N" 2 "R" 1 "P" ;
VAL_ 401 GEAR 7 "L" 10 "S" 4 "D" 3 "N" 2 "R" 1 "P" ;
VAL_ 545 ECON_ON_2 0 "off" 3 "on" ;
VAL_ 662 CRUISE_BUTTONS 7 "tbd" 6 "tbd" 5 "tbd" 4 "accel_res" 3 "decel_set" 2 "cancel" 1 "main" 0 "none" ;
VAL_ 662 CRUISE_SETTING 3 "distance_adj" 2 "tbd" 1 "lkas_button" 0 "none" ;
